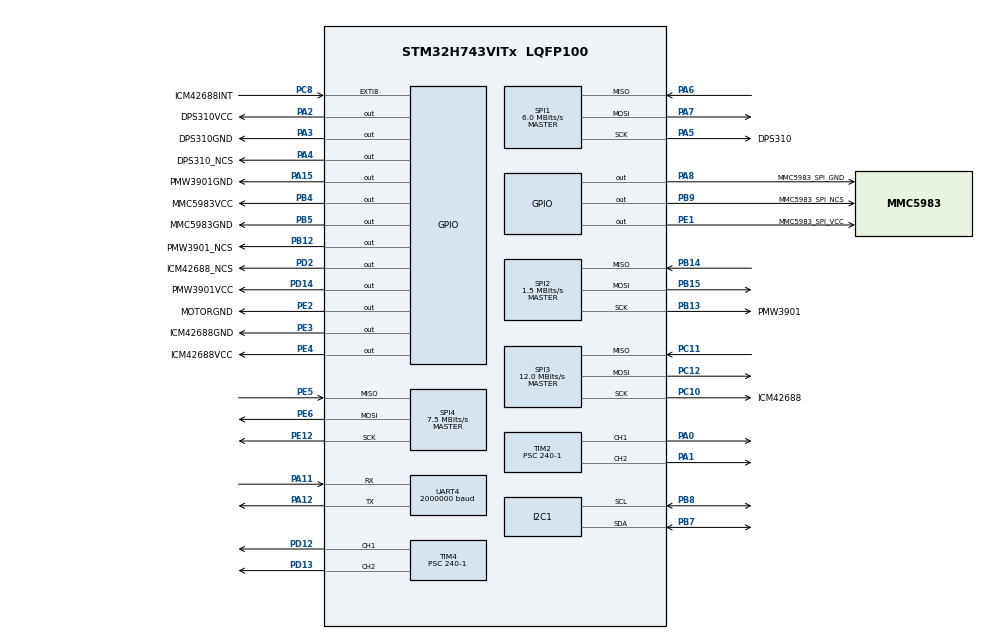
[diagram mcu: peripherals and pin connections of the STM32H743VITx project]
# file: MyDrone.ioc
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CORTEX_M7.CPU_DCache=Enabled
CORTEX_M7.CPU_ICache=Enabled
CORTEX_M7.default_mode_Activation=1
Dma.I2C1_RX.4.Direction=DMA_PERIPH_TO_MEMORY
Dma.I2C1_RX.4.EventEnable=DISABLE
Dma.I2C1_RX.4.FIFOMode=DMA_FIFOMODE_DISABLE
Dma.I2C1_RX.4.Instance=DMA1_Stream0
Dma.I2C1_RX.4.MemDataAlignment=DMA_MDATAALIGN_BYTE
Dma.I2C1_RX.4.MemInc=DMA_MINC_ENABLE
Dma.I2C1_RX.4.Mode=DMA_NORMAL
Dma.I2C1_RX.4.PeriphDataAlignment=DMA_PDATAALIGN_BYTE
Dma.I2C1_RX.4.PeriphInc=DMA_PINC_DISABLE
Dma.I2C1_RX.4.Polarity=HAL_DMAMUX_REQ_GEN_RISING
Dma.I2C1_RX.4.Priority=DMA_PRIORITY_LOW
Dma.I2C1_RX.4.RequestNumber=1
Dma.I2C1_RX.4.SignalID=NONE
Dma.I2C1_RX.4.SyncEnable=DISABLE
Dma.I2C1_RX.4.SyncPolarity=HAL_DMAMUX_SYNC_NO_EVENT
Dma.I2C1_RX.4.SyncRequestNumber=1
Dma.I2C1_RX.4.SyncSignalID=NONE
Dma.I2C1_TX.5.Direction=DMA_MEMORY_TO_PERIPH
Dma.I2C1_TX.5.EventEnable=DISABLE
Dma.I2C1_TX.5.FIFOMode=DMA_FIFOMODE_DISABLE
Dma.I2C1_TX.5.Instance=DMA1_Stream7
Dma.I2C1_TX.5.MemDataAlignment=DMA_MDATAALIGN_BYTE
Dma.I2C1_TX.5.MemInc=DMA_MINC_ENABLE
Dma.I2C1_TX.5.Mode=DMA_NORMAL
Dma.I2C1_TX.5.PeriphDataAlignment=DMA_PDATAALIGN_BYTE
Dma.I2C1_TX.5.PeriphInc=DMA_PINC_DISABLE
Dma.I2C1_TX.5.Polarity=HAL_DMAMUX_REQ_GEN_RISING
Dma.I2C1_TX.5.Priority=DMA_PRIORITY_LOW
Dma.I2C1_TX.5.RequestNumber=1
Dma.I2C1_TX.5.SignalID=NONE
Dma.I2C1_TX.5.SyncEnable=DISABLE
Dma.I2C1_TX.5.SyncPolarity=HAL_DMAMUX_SYNC_NO_EVENT
Dma.I2C1_TX.5.SyncRequestNumber=1
Dma.I2C1_TX.5.SyncSignalID=NONE
Dma.Request0=SPI1_RX
Dma.Request1=SPI1_TX
Dma.Request2=SPI2_RX
Dma.Request3=SPI2_TX
Dma.Request4=I2C1_RX
Dma.Request5=I2C1_TX
Dma.Request6=UART4_RX
Dma.Request7=UART4_TX
Dma.Request8=SPI4_RX
Dma.Request9=SPI4_TX
Dma.SPI1_RX.0.Direction=DMA_PERIPH_TO_MEMORY
Dma.SPI1_RX.0.EventEnable=DISABLE
Dma.SPI1_RX.0.FIFOMode=DMA_FIFOMODE_DISABLE
Dma.SPI1_RX.0.Instance=DMA1_Stream1
Dma.SPI1_RX.0.MemDataAlignment=DMA_MDATAALIGN_BYTE
Dma.SPI1_RX.0.MemInc=DMA_MINC_ENABLE
Dma.SPI1_RX.0.Mode=DMA_NORMAL
Dma.SPI1_RX.0.PeriphDataAlignment=DMA_PDATAALIGN_BYTE
Dma.SPI1_RX.0.PeriphInc=DMA_PINC_DISABLE
Dma.SPI1_RX.0.Polarity=HAL_DMAMUX_REQ_GEN_RISING
Dma.SPI1_RX.0.Priority=DMA_PRIORITY_LOW
Dma.SPI1_RX.0.RequestNumber=1
Dma.SPI1_RX.0.SignalID=NONE
Dma.SPI1_RX.0.SyncEnable=DISABLE
Dma.SPI1_RX.0.SyncPolarity=HAL_DMAMUX_SYNC_NO_EVENT
Dma.SPI1_RX.0.SyncRequestNumber=1
Dma.SPI1_RX.0.SyncSignalID=NONE
Dma.SPI1_TX.1.Direction=DMA_MEMORY_TO_PERIPH
Dma.SPI1_TX.1.EventEnable=DISABLE
Dma.SPI1_TX.1.FIFOMode=DMA_FIFOMODE_DISABLE
Dma.SPI1_TX.1.Instance=DMA1_Stream2
Dma.SPI1_TX.1.MemDataAlignment=DMA_MDATAALIGN_BYTE
Dma.SPI1_TX.1.MemInc=DMA_MINC_ENABLE
Dma.SPI1_TX.1.Mode=DMA_NORMAL
Dma.SPI1_TX.1.PeriphDataAlignment=DMA_PDATAALIGN_BYTE
Dma.SPI1_TX.1.PeriphInc=DMA_PINC_DISABLE
Dma.SPI1_TX.1.Polarity=HAL_DMAMUX_REQ_GEN_RISING
Dma.SPI1_TX.1.Priority=DMA_PRIORITY_LOW
Dma.SPI1_TX.1.RequestNumber=1
Dma.SPI1_TX.1.SignalID=NONE
Dma.SPI1_TX.1.SyncEnable=DISABLE
Dma.SPI1_TX.1.SyncPolarity=HAL_DMAMUX_SYNC_NO_EVENT
Dma.SPI1_TX.1.SyncRequestNumber=1
Dma.SPI1_TX.1.SyncSignalID=NONE
Dma.SPI2_RX.2.Direction=DMA_PERIPH_TO_MEMORY
Dma.SPI2_RX.2.EventEnable=DISABLE
Dma.SPI2_RX.2.FIFOMode=DMA_FIFOMODE_DISABLE
Dma.SPI2_RX.2.Instance=DMA1_Stream3
Dma.SPI2_RX.2.MemDataAlignment=DMA_MDATAALIGN_BYTE
Dma.SPI2_RX.2.MemInc=DMA_MINC_ENABLE
Dma.SPI2_RX.2.Mode=DMA_NORMAL
Dma.SPI2_RX.2.PeriphDataAlignment=DMA_PDATAALIGN_BYTE
Dma.SPI2_RX.2.PeriphInc=DMA_PINC_DISABLE
Dma.SPI2_RX.2.Polarity=HAL_DMAMUX_REQ_GEN_RISING
Dma.SPI2_RX.2.Priority=DMA_PRIORITY_LOW
Dma.SPI2_RX.2.RequestNumber=1
Dma.SPI2_RX.2.SignalID=NONE
Dma.SPI2_RX.2.SyncEnable=DISABLE
Dma.SPI2_RX.2.SyncPolarity=HAL_DMAMUX_SYNC_NO_EVENT
Dma.SPI2_RX.2.SyncRequestNumber=1
Dma.SPI2_RX.2.SyncSignalID=NONE
Dma.SPI2_TX.3.Direction=DMA_MEMORY_TO_PERIPH
Dma.SPI2_TX.3.EventEnable=DISABLE
Dma.SPI2_TX.3.FIFOMode=DMA_FIFOMODE_DISABLE
Dma.SPI2_TX.3.Instance=DMA1_Stream4
Dma.SPI2_TX.3.MemDataAlignment=DMA_MDATAALIGN_BYTE
Dma.SPI2_TX.3.MemInc=DMA_MINC_ENABLE
Dma.SPI2_TX.3.Mode=DMA_NORMAL
Dma.SPI2_TX.3.PeriphDataAlignment=DMA_PDATAALIGN_BYTE
Dma.SPI2_TX.3.PeriphInc=DMA_PINC_DISABLE
Dma.SPI2_TX.3.Polarity=HAL_DMAMUX_REQ_GEN_RISING
Dma.SPI2_TX.3.Priority=DMA_PRIORITY_LOW
Dma.SPI2_TX.3.RequestNumber=1
Dma.SPI2_TX.3.SignalID=NONE
Dma.SPI2_TX.3.SyncEnable=DISABLE
Dma.SPI2_TX.3.SyncPolarity=HAL_DMAMUX_SYNC_NO_EVENT
Dma.SPI2_TX.3.SyncRequestNumber=1
Dma.SPI2_TX.3.SyncSignalID=NONE
Dma.SPI4_RX.8.Direction=DMA_PERIPH_TO_MEMORY
Dma.SPI4_RX.8.EventEnable=DISABLE
Dma.SPI4_RX.8.FIFOMode=DMA_FIFOMODE_DISABLE
Dma.SPI4_RX.8.Instance=DMA2_Stream0
Dma.SPI4_RX.8.MemDataAlignment=DMA_MDATAALIGN_BYTE
Dma.SPI4_RX.8.MemInc=DMA_MINC_ENABLE
Dma.SPI4_RX.8.Mode=DMA_NORMAL
Dma.SPI4_RX.8.PeriphDataAlignment=DMA_PDATAALIGN_BYTE
Dma.SPI4_RX.8.PeriphInc=DMA_PINC_DISABLE
Dma.SPI4_RX.8.Polarity=HAL_DMAMUX_REQ_GEN_RISING
Dma.SPI4_RX.8.Priority=DMA_PRIORITY_LOW
Dma.SPI4_RX.8.RequestNumber=1
Dma.SPI4_RX.8.SignalID=NONE
Dma.SPI4_RX.8.SyncEnable=DISABLE
Dma.SPI4_RX.8.SyncPolarity=HAL_DMAMUX_SYNC_NO_EVENT
Dma.SPI4_RX.8.SyncRequestNumber=1
Dma.SPI4_RX.8.SyncSignalID=NONE
Dma.SPI4_TX.9.Direction=DMA_MEMORY_TO_PERIPH
Dma.SPI4_TX.9.EventEnable=DISABLE
Dma.SPI4_TX.9.FIFOMode=DMA_FIFOMODE_DISABLE
Dma.SPI4_TX.9.Instance=DMA2_Stream1
Dma.SPI4_TX.9.MemDataAlignment=DMA_MDATAALIGN_BYTE
Dma.SPI4_TX.9.MemInc=DMA_MINC_ENABLE
Dma.SPI4_TX.9.Mode=DMA_NORMAL
Dma.SPI4_TX.9.PeriphDataAlignment=DMA_PDATAALIGN_BYTE
Dma.SPI4_TX.9.PeriphInc=DMA_PINC_DISABLE
Dma.SPI4_TX.9.Polarity=HAL_DMAMUX_REQ_GEN_RISING
Dma.SPI4_TX.9.Priority=DMA_PRIORITY_LOW
Dma.SPI4_TX.9.RequestNumber=1
Dma.SPI4_TX.9.SignalID=NONE
Dma.SPI4_TX.9.SyncEnable=DISABLE
Dma.SPI4_TX.9.SyncPolarity=HAL_DMAMUX_SYNC_NO_EVENT
Dma.SPI4_TX.9.SyncRequestNumber=1
Dma.SPI4_TX.9.SyncSignalID=NONE
Dma.UART4_RX.6.Direction=DMA_PERIPH_TO_MEMORY
Dma.UART4_RX.6.EventEnable=DISABLE
Dma.UART4_RX.6.FIFOMode=DMA_FIFOMODE_DISABLE
Dma.UART4_RX.6.Instance=DMA1_Stream5
Dma.UART4_RX.6.MemDataAlignment=DMA_MDATAALIGN_BYTE
Dma.UART4_RX.6.MemInc=DMA_MINC_ENABLE
Dma.UART4_RX.6.Mode=DMA_CIRCULAR
Dma.UART4_RX.6.PeriphDataAlignment=DMA_PDATAALIGN_BYTE
Dma.UART4_RX.6.PeriphInc=DMA_PINC_DISABLE
Dma.UART4_RX.6.Polarity=HAL_DMAMUX_REQ_GEN_RISING
Dma.UART4_RX.6.Priority=DMA_PRIORITY_HIGH
Dma.UART4_RX.6.RequestNumber=1
Dma.UART4_RX.6.SignalID=NONE
Dma.UART4_RX.6.SyncEnable=DISABLE
Dma.UART4_RX.6.SyncPolarity=HAL_DMAMUX_SYNC_NO_EVENT
Dma.UART4_RX.6.SyncRequestNumber=1
Dma.UART4_RX.6.SyncSignalID=NONE
Dma.UART4_TX.7.Direction=DMA_MEMORY_TO_PERIPH
Dma.UART4_TX.7.EventEnable=DISABLE
Dma.UART4_TX.7.FIFOMode=DMA_FIFOMODE_DISABLE
Dma.UART4_TX.7.Instance=DMA1_Stream6
Dma.UART4_TX.7.MemDataAlignment=DMA_MDATAALIGN_BYTE
Dma.UART4_TX.7.MemInc=DMA_MINC_ENABLE
Dma.UART4_TX.7.Mode=DMA_NORMAL
Dma.UART4_TX.7.PeriphDataAlignment=DMA_PDATAALIGN_BYTE
Dma.UART4_TX.7.PeriphInc=DMA_PINC_DISABLE
Dma.UART4_TX.7.Polarity=HAL_DMAMUX_REQ_GEN_RISING
Dma.UART4_TX.7.Priority=DMA_PRIORITY_HIGH
Dma.UART4_TX.7.RequestNumber=1
Dma.UART4_TX.7.SignalID=NONE
Dma.UART4_TX.7.SyncEnable=DISABLE
Dma.UART4_TX.7.SyncPolarity=HAL_DMAMUX_SYNC_NO_EVENT
Dma.UART4_TX.7.SyncRequestNumber=1
Dma.UART4_TX.7.SyncSignalID=NONE
FREERTOS.HEAP_NUMBER=4
FREERTOS.Tasks01=defaultTask,24,128,StartDefaultTask,Default,NULL,Dynamic,NULL,NULL
FREERTOS.configCHECK_FOR_STACK_OVERFLOW=2
FREERTOS.configENABLE_FPU=1
FREERTOS.configTIMER_TASK_PRIORITY=40
FREERTOS.configTOTAL_HEAP_SIZE=131072
I2C1.Timing=0x307075B1
Mcu.Family=STM32H7
Mcu.Name=STM32H743VITx
Mcu.Package=LQFP100
NVIC.DMA1_Stream0_IRQn=true\:5\:0\:false\:false\:true\:true\:false\:true\:true
NVIC.DMA1_Stream1_IRQn=true\:5\:0\:false\:false\:true\:true\:false\:true\:true
NVIC.DMA1_Stream2_IRQn=true\:5\:0\:false\:false\:true\:true\:false\:true\:true
NVIC.DMA1_Stream3_IRQn=true\:5\:0\:false\:false\:true\:true\:false\:true\:true
NVIC.DMA1_Stream4_IRQn=true\:5\:0\:false\:false\:true\:true\:false\:true\:true
NVIC.DMA1_Stream5_IRQn=true\:5\:0\:false\:false\:true\:true\:false\:true\:true
NVIC.DMA1_Stream6_IRQn=true\:5\:0\:false\:false\:true\:true\:false\:true\:true
NVIC.DMA1_Stream7_IRQn=true\:5\:0\:false\:false\:true\:true\:false\:true\:true
NVIC.DMA2_Stream0_IRQn=true\:5\:0\:false\:false\:true\:true\:false\:true\:true
NVIC.DMA2_Stream1_IRQn=true\:5\:0\:false\:false\:true\:true\:false\:true\:true
NVIC.EXTI9_5_IRQn=true\:5\:0\:false\:false\:true\:true\:true\:true\:true
NVIC.I2C1_ER_IRQn=true\:5\:0\:false\:false\:true\:true\:true\:true\:true
NVIC.I2C1_EV_IRQn=true\:5\:0\:false\:false\:true\:true\:true\:true\:true
NVIC.PriorityGroup=NVIC_PRIORITYGROUP_4
NVIC.SPI1_IRQn=true\:5\:0\:false\:false\:true\:true\:false\:true\:true
NVIC.SPI2_IRQn=true\:5\:0\:false\:false\:true\:true\:false\:true\:true
NVIC.SPI3_IRQn=true\:5\:0\:false\:false\:true\:true\:true\:true\:true
NVIC.SPI4_IRQn=true\:5\:0\:false\:false\:true\:true\:false\:true\:true
NVIC.TIM7_IRQn=true\:15\:0\:true\:false\:true\:false\:false\:true\:true
NVIC.TimeBase=TIM7_IRQn
NVIC.TimeBaseIP=TIM7
NVIC.UART4_IRQn=true\:5\:0\:false\:false\:true\:true\:true\:true\:true
PA0.Signal=S_TIM2_CH1_ETR
PA1.Signal=S_TIM2_CH2
PA11.GPIO_PuPd=GPIO_PULLUP
PA11.GPIO_Speed=GPIO_SPEED_FREQ_VERY_HIGH
PA11.Mode=Asynchronous
PA11.Signal=UART4_RX
PA12.GPIO_Speed=GPIO_SPEED_FREQ_VERY_HIGH
PA12.Mode=Asynchronous
PA12.Signal=UART4_TX
PA13\ (JTMS/SWDIO).Mode=Serial_Wire
PA13\ (JTMS/SWDIO).Signal=DEBUG_JTMS-SWDIO
PA14\ (JTCK/SWCLK).Mode=Serial_Wire
PA14\ (JTCK/SWCLK).Signal=DEBUG_JTCK-SWCLK
PA15\ (JTDI).GPIO_Label=PMW3901GND
PA15\ (JTDI).Signal=GPIO_Output
PA2.GPIO_Label=DPS310VCC
PA2.PinState=GPIO_PIN_SET
PA2.Signal=GPIO_Output
PA3.GPIO_Label=DPS310GND
PA3.Signal=GPIO_Output
PA4.GPIO_Label=DPS310_NCS
PA4.GPIO_Speed=GPIO_SPEED_FREQ_VERY_HIGH
PA4.PinState=GPIO_PIN_SET
PA4.Signal=GPIO_Output
PA5.GPIO_Label=DPS310
PA5.Mode=Full_Duplex_Master
PA5.Signal=SPI1_SCK
PA6.Mode=Full_Duplex_Master
PA6.Signal=SPI1_MISO
PA7.Mode=Full_Duplex_Master
PA7.Signal=SPI1_MOSI
PA8.GPIO_Label=MMC5983_SPI_GND
PA8.Signal=GPIO_Output
PB12.GPIO_Label=PMW3901_NCS
PB12.GPIO_Speed=GPIO_SPEED_FREQ_VERY_HIGH
PB12.PinState=GPIO_PIN_SET
PB12.Signal=GPIO_Output
PB13.GPIO_Label=PMW3901
PB13.Mode=Full_Duplex_Master
PB13.Signal=SPI2_SCK
PB14.Mode=Full_Duplex_Master
PB14.Signal=SPI2_MISO
PB15.Mode=Full_Duplex_Master
PB15.Signal=SPI2_MOSI
PB4\ (NJTRST).GPIO_Label=MMC5983VCC
PB4\ (NJTRST).PinState=GPIO_PIN_SET
PB4\ (NJTRST).Signal=GPIO_Output
PB5.GPIO_Label=MMC5983GND
PB5.Signal=GPIO_Output
PB7.GPIO_Speed=GPIO_SPEED_FREQ_VERY_HIGH
PB7.Mode=I2C
PB7.Signal=I2C1_SDA
PB8.GPIO_Speed=GPIO_SPEED_FREQ_VERY_HIGH
PB8.Mode=I2C
PB8.Signal=I2C1_SCL
PB9.GPIO_Label=MMC5983_SPI_NCS
PB9.GPIO_Speed=GPIO_SPEED_FREQ_VERY_HIGH
PB9.PinState=GPIO_PIN_SET
PB9.Signal=GPIO_Output
PC10.GPIO_Label=ICM42688
PC10.Mode=Full_Duplex_Master
PC10.Signal=SPI3_SCK
PC11.Mode=Full_Duplex_Master
PC11.Signal=SPI3_MISO
PC12.Mode=Full_Duplex_Master
PC12.Signal=SPI3_MOSI
PC8.GPIO_Label=ICM42688INT
PC8.Signal=GPXTI8
PD12.Signal=S_TIM4_CH1
PD13.Signal=S_TIM4_CH2
PD14.GPIO_Label=PMW3901VCC
PD14.PinState=GPIO_PIN_SET
PD14.Signal=GPIO_Output
PD2.GPIO_Label=ICM42688_NCS
PD2.GPIO_Speed=GPIO_SPEED_FREQ_VERY_HIGH
PD2.PinState=GPIO_PIN_SET
PD2.Signal=GPIO_Output
PE1.GPIO_Label=MMC5983_SPI_VCC
PE1.PinState=GPIO_PIN_SET
PE1.Signal=GPIO_Output
PE12.Mode=Full_Duplex_Master
PE12.Signal=SPI4_SCK
PE2.GPIO_Label=MOTORGND
PE2.Signal=GPIO_Output
PE3.GPIO_Label=ICM42688GND
PE3.Signal=GPIO_Output
PE4.GPIO_Label=ICM42688VCC
PE4.PinState=GPIO_PIN_SET
PE4.Signal=GPIO_Output
PE5.Mode=Full_Duplex_Master
PE5.Signal=SPI4_MISO
PE6.Mode=Full_Duplex_Master
PE6.Signal=SPI4_MOSI
PH0-OSC_IN\ (PH0).Mode=HSE-External-Oscillator
PH0-OSC_IN\ (PH0).Signal=RCC_OSC_IN
PH1-OSC_OUT\ (PH1).Mode=HSE-External-Oscillator
PH1-OSC_OUT\ (PH1).Signal=RCC_OSC_OUT
ProjectManager.HeapSize=0x200
ProjectManager.StackSize=0x400
ProjectManager.TargetToolchain=STM32CubeIDE
RCC.ADCFreq_Value=50390625
RCC.APB1Freq_Value=120000000
RCC.APB2Freq_Value=120000000
RCC.APB3Freq_Value=120000000
RCC.APB4Freq_Value=120000000
RCC.CortexFreq_Value=480000000
RCC.D1PPRE=RCC_APB3_DIV2
RCC.D2PPRE1=RCC_APB1_DIV2
RCC.D2PPRE2=RCC_APB2_DIV2
RCC.D3PPRE=RCC_APB4_DIV2
RCC.DIVM1=5
RCC.DIVN1=192
RCC.DIVQ1=5
RCC.HCLKFreq_Value=240000000
RCC.HPRE=RCC_HCLK_DIV2
RCC.PLLFRACN=0
RCC.PLLSourceVirtual=RCC_PLLSOURCE_HSE
RCC.PWR_Regulator_Voltage_Scale=PWR_REGULATOR_VOLTAGE_SCALE0
RCC.SYSCLKFreq_VALUE=480000000
RCC.SYSCLKSource=RCC_SYSCLKSOURCE_PLLCLK
RCC.USBFreq_Value=192000000
SH.S_TIM2_CH1_ETR.0=TIM2_CH1,PWM Generation1 CH1
SH.S_TIM2_CH2.0=TIM2_CH2,PWM Generation2 CH2
SH.S_TIM4_CH1.0=TIM4_CH1,PWM Generation1 CH1
SH.S_TIM4_CH2.0=TIM4_CH2,PWM Generation2 CH2
SPI1.BaudRatePrescaler=SPI_BAUDRATEPRESCALER_32
SPI1.CLKPhase=SPI_PHASE_2EDGE
SPI1.CLKPolarity=SPI_POLARITY_HIGH
SPI1.CalculateBaudRate=6.0 MBits/s
SPI1.DataSize=SPI_DATASIZE_8BIT
SPI1.Direction=SPI_DIRECTION_2LINES
SPI1.Mode=SPI_MODE_MASTER
SPI1.VirtualType=VM_MASTER
SPI2.BaudRatePrescaler=SPI_BAUDRATEPRESCALER_128
SPI2.CLKPhase=SPI_PHASE_2EDGE
SPI2.CLKPolarity=SPI_POLARITY_HIGH
SPI2.CalculateBaudRate=1.5 MBits/s
SPI2.DataSize=SPI_DATASIZE_8BIT
SPI2.Direction=SPI_DIRECTION_2LINES
SPI2.Mode=SPI_MODE_MASTER
SPI2.VirtualType=VM_MASTER
SPI3.BaudRatePrescaler=SPI_BAUDRATEPRESCALER_16
SPI3.CLKPhase=SPI_PHASE_2EDGE
SPI3.CLKPolarity=SPI_POLARITY_HIGH
SPI3.CalculateBaudRate=12.0 MBits/s
SPI3.DataSize=SPI_DATASIZE_8BIT
SPI3.Direction=SPI_DIRECTION_2LINES
SPI3.Mode=SPI_MODE_MASTER
SPI3.VirtualType=VM_MASTER
SPI4.BaudRatePrescaler=SPI_BAUDRATEPRESCALER_16
SPI4.CLKPhase=SPI_PHASE_2EDGE
SPI4.CLKPolarity=SPI_POLARITY_HIGH
SPI4.CalculateBaudRate=7.5 MBits/s
SPI4.DataSize=SPI_DATASIZE_8BIT
SPI4.Direction=SPI_DIRECTION_2LINES
SPI4.Mode=SPI_MODE_MASTER
SPI4.VirtualType=VM_MASTER
TIM2.Channel-PWM\ Generation1\ CH1=TIM_CHANNEL_1
TIM2.Channel-PWM\ Generation2\ CH2=TIM_CHANNEL_2
TIM2.Period=2000
TIM2.Prescaler=240-1
TIM2.Pulse-PWM\ Generation1\ CH1=1220
TIM2.Pulse-PWM\ Generation2\ CH2=1220
TIM4.Channel-PWM\ Generation1\ CH1=TIM_CHANNEL_1
TIM4.Channel-PWM\ Generation2\ CH2=TIM_CHANNEL_2
TIM4.Period=2000
TIM4.Prescaler=240-1
TIM4.Pulse-PWM\ Generation1\ CH1=1220
TIM4.Pulse-PWM\ Generation2\ CH2=1220
UART4.BaudRate=2000000
UART4.FIFOMode=FIFOMODE_ENABLE
VP_FREERTOS_VS_CMSIS_V2.Mode=CMSIS_V2
VP_MEMORYMAP_VS_MEMORYMAP.Mode=CurAppReg
VP_SYS_VS_tim7.Mode=TIM7
board=custom

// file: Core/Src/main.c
/* USER CODE BEGIN Header */
/**
 ******************************************************************************
 * @file           : main.c
 * @brief          : Main program body
 ******************************************************************************
 * @attention
 *
 * Copyright (c) 2026 STMicroelectronics.
 * All rights reserved.
 *
 * This software is licensed under terms that can be found in the LICENSE file
 * in the root directory of this software component.
 * If no LICENSE file comes with this software, it is provided AS-IS.
 *
 ******************************************************************************
 */
/* USER CODE END Header */
#include "main.h"
#include "cmsis_os.h"
#include "dma.h"
#include "i2c.h"
#include "spi.h"
#include "tim.h"
#include "usart.h"
#include "gpio.h"

/* USER CODE BEGIN Includes */
#include "DTCMinit.h"
#include "Mydelay.hpp"
#include "TaskConfig.hpp"
/* USER CODE END Includes */

/* USER CODE BEGIN PM */
volatile float Mag_Gauss_x = 0;
volatile float Mag_Gauss_y = 0;
volatile float Mag_Gauss_z = 0;
/* USER CODE END PM */

void SystemClock_Config(void);
static void MPU_Config(void);
void MX_FREERTOS_Init(void);

int main(void)
{

  /* USER CODE BEGIN 1 */
    System_DTCM_Init(); // 初始化 DTCM 内存
  /* USER CODE END 1 */

  /* MPU Configuration--------------------------------------------------------*/
  MPU_Config();

  /* Enable the CPU Cache */

  /* Enable I-Cache---------------------------------------------------------*/
  SCB_EnableICache();

  /* Enable D-Cache---------------------------------------------------------*/
  SCB_EnableDCache();

  /* MCU Configuration--------------------------------------------------------*/

  /* Reset of all peripherals, Initializes the Flash interface and the Systick. */
  HAL_Init();

  /* Configure the system clock */
  SystemClock_Config();

  /* USER CODE BEGIN SysInit */
    DWT_Time_Init(); // 初始化 DWT 计数器
  /* USER CODE END SysInit */

  /* Initialize all configured peripherals */
  MX_GPIO_Init();
  MX_DMA_Init();
  MX_SPI1_Init();
  MX_SPI2_Init();
  MX_SPI3_Init();
  MX_TIM2_Init();
  MX_TIM4_Init();
  MX_I2C1_Init();
  MX_UART4_Init();
  MX_SPI4_Init();
  /* USER CODE BEGIN 2 */
    Bridge_System_Init(); // 初始化传感器系统
  /* USER CODE END 2 */

  /* Init scheduler */
  osKernelInitialize();  /* Call init function for freertos objects (in cmsis_os2.c) */
  MX_FREERTOS_Init();

  /* Start scheduler */
  osKernelStart();

  /* We should never get here as control is now taken by the scheduler */

  /* Infinite loop */
    while (1)
    {

    }
}

void SystemClock_Config(void)
{
  RCC_OscInitTypeDef RCC_OscInitStruct = {0};
  RCC_ClkInitTypeDef RCC_ClkInitStruct = {0};

  /** Supply configuration update enable
  */
  HAL_PWREx_ConfigSupply(PWR_LDO_SUPPLY);

  /** Configure the main internal regulator output voltage
  */
  __HAL_PWR_VOLTAGESCALING_CONFIG(PWR_REGULATOR_VOLTAGE_SCALE0);

  while(!__HAL_PWR_GET_FLAG(PWR_FLAG_VOSRDY)) {}

  /** Initializes the RCC Oscillators according to the specified parameters
  * in the RCC_OscInitTypeDef structure.
  */
  RCC_OscInitStruct.OscillatorType = RCC_OSCILLATORTYPE_HSE;
  RCC_OscInitStruct.HSEState = RCC_HSE_ON;
  RCC_OscInitStruct.PLL.PLLState = RCC_PLL_ON;
  RCC_OscInitStruct.PLL.PLLSource = RCC_PLLSOURCE_HSE;
  RCC_OscInitStruct.PLL.PLLM = 5;
  RCC_OscInitStruct.PLL.PLLN = 192;
  RCC_OscInitStruct.PLL.PLLP = 2;
  RCC_OscInitStruct.PLL.PLLQ = 5;
  RCC_OscInitStruct.PLL.PLLR = 2;
  RCC_OscInitStruct.PLL.PLLRGE = RCC_PLL1VCIRANGE_2;
  RCC_OscInitStruct.PLL.PLLVCOSEL = RCC_PLL1VCOWIDE;
  RCC_OscInitStruct.PLL.PLLFRACN = 0;
  if (HAL_RCC_OscConfig(&RCC_OscInitStruct) != HAL_OK)
  {
    Error_Handler();
  }

  /** Initializes the CPU, AHB and APB buses clocks
  */
  RCC_ClkInitStruct.ClockType = RCC_CLOCKTYPE_HCLK|RCC_CLOCKTYPE_SYSCLK
                              |RCC_CLOCKTYPE_PCLK1|RCC_CLOCKTYPE_PCLK2
                              |RCC_CLOCKTYPE_D3PCLK1|RCC_CLOCKTYPE_D1PCLK1;
  RCC_ClkInitStruct.SYSCLKSource = RCC_SYSCLKSOURCE_PLLCLK;
  RCC_ClkInitStruct.SYSCLKDivider = RCC_SYSCLK_DIV1;
  RCC_ClkInitStruct.AHBCLKDivider = RCC_HCLK_DIV2;
  RCC_ClkInitStruct.APB3CLKDivider = RCC_APB3_DIV2;
  RCC_ClkInitStruct.APB1CLKDivider = RCC_APB1_DIV2;
  RCC_ClkInitStruct.APB2CLKDivider = RCC_APB2_DIV2;
  RCC_ClkInitStruct.APB4CLKDivider = RCC_APB4_DIV2;

  if (HAL_RCC_ClockConfig(&RCC_ClkInitStruct, FLASH_LATENCY_4) != HAL_OK)
  {
    Error_Handler();
  }
}

 /* MPU Configuration */

void MPU_Config(void)
{
  MPU_Region_InitTypeDef MPU_InitStruct = {0};

  /* Disables the MPU */
  HAL_MPU_Disable();

  /** Initializes and configures the Region and the memory to be protected
  */
  MPU_InitStruct.Enable = MPU_REGION_ENABLE;
  MPU_InitStruct.Number = MPU_REGION_NUMBER0;
  MPU_InitStruct.BaseAddress = 0x0;
  MPU_InitStruct.Size = MPU_REGION_SIZE_4GB;
  MPU_InitStruct.SubRegionDisable = 0x87;
  MPU_InitStruct.TypeExtField = MPU_TEX_LEVEL0;
  MPU_InitStruct.AccessPermission = MPU_REGION_NO_ACCESS;
  MPU_InitStruct.DisableExec = MPU_INSTRUCTION_ACCESS_DISABLE;
  MPU_InitStruct.IsShareable = MPU_ACCESS_SHAREABLE;
  MPU_InitStruct.IsCacheable = MPU_ACCESS_NOT_CACHEABLE;
  MPU_InitStruct.IsBufferable = MPU_ACCESS_NOT_BUFFERABLE;

  HAL_MPU_ConfigRegion(&MPU_InitStruct);
  /* Enables the MPU */
  HAL_MPU_Enable(MPU_PRIVILEGED_DEFAULT);

}

void HAL_TIM_PeriodElapsedCallback(TIM_HandleTypeDef *htim)
{
  if (htim->Instance == TIM7)
  {
    HAL_IncTick();
  }
}

void Error_Handler(void)
{
    __disable_irq();
    while (1)
    {
    }
}
